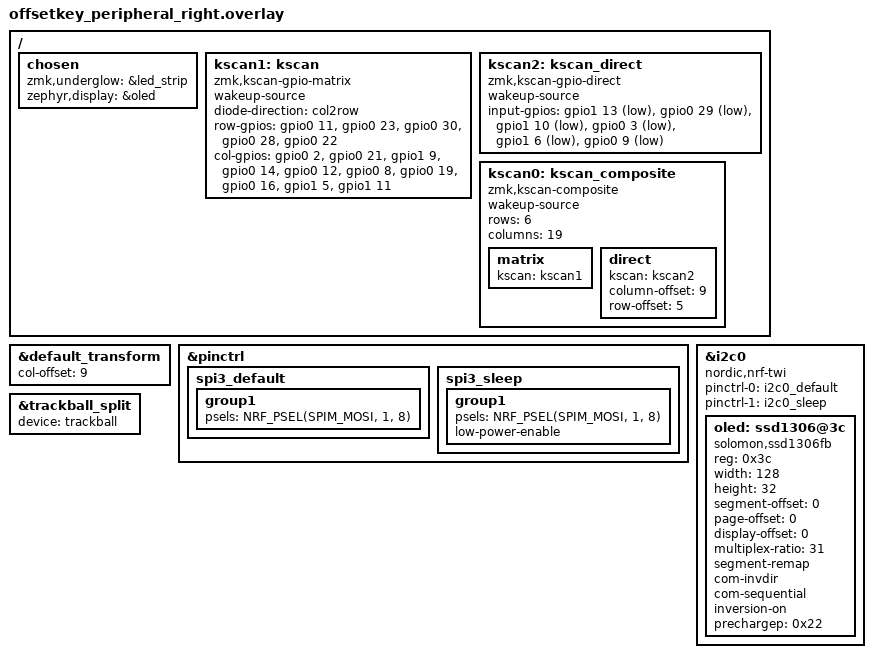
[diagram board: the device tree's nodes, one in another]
/*
 * Copyright (c) 2020 ZMK Contributors
 *
 * SPDX-License-Identifier: MIT
 */
#include <dt-bindings/zmk/input_transform.h>
#include <input/processors.dtsi>
#include <dt-bindings/led/led.h>
#include "offsetkey.dtsi"
#include "trackball.dtsi"
#include "split_input_common.dtsi"
#define SYMBOLS 2
#include "rgb.dtsi"

/ {
	chosen {
        zmk,underglow = &led_strip;
        zephyr,display = &oled;
    };

    kscan1: kscan {
        wakeup-source;
        diode-direction = "col2row";
        compatible = "zmk,kscan-gpio-matrix";
        row-gpios
            = <&gpio0 11 (GPIO_ACTIVE_HIGH | GPIO_PULL_DOWN)>
            , <&gpio0 23 (GPIO_ACTIVE_HIGH | GPIO_PULL_DOWN)>
            , <&gpio0 30  (GPIO_ACTIVE_HIGH | GPIO_PULL_DOWN)>
            , <&gpio0 28 (GPIO_ACTIVE_HIGH | GPIO_PULL_DOWN)>
            , <&gpio0 22 (GPIO_ACTIVE_HIGH | GPIO_PULL_DOWN)>
            ;
        col-gpios
            =  <&gpio0 2  GPIO_ACTIVE_HIGH>
            ,  <&gpio0 21  GPIO_ACTIVE_HIGH>
            , <&gpio1 9  GPIO_ACTIVE_HIGH>
            , <&gpio0 14  GPIO_ACTIVE_HIGH>
            , <&gpio0 12  GPIO_ACTIVE_HIGH>
            , <&gpio0 8  GPIO_ACTIVE_HIGH>  
            , <&gpio0 19  GPIO_ACTIVE_HIGH>  
            , <&gpio0 16  GPIO_ACTIVE_HIGH>  
            , <&gpio1 5  GPIO_ACTIVE_HIGH> 
            , <&gpio1 11 GPIO_ACTIVE_HIGH> 
            ;
    };

    kscan2: kscan_direct {
        compatible = "zmk,kscan-gpio-direct";
        wakeup-source;
        input-gpios
            = <&gpio1 13 (GPIO_ACTIVE_LOW | GPIO_PULL_UP)>
            , <&gpio0 29 (GPIO_ACTIVE_LOW | GPIO_PULL_UP)>
            , <&gpio1 10 (GPIO_ACTIVE_LOW | GPIO_PULL_UP)>
            , <&gpio0 3 (GPIO_ACTIVE_LOW | GPIO_PULL_UP)>
            , <&gpio1 6 (GPIO_ACTIVE_LOW | GPIO_PULL_UP)>
            , <&gpio0 9 (GPIO_ACTIVE_LOW | GPIO_PULL_UP)>
            ;
    };
//only 1.04 1.07 remain
    kscan0: kscan_composite {
        compatible = "zmk,kscan-composite";
         wakeup-source;
        rows = <6>;
        columns = <19>;

        // Include the matrix driver
        matrix {
            kscan = <&kscan1>;
        };

        // Include the direct GPIO driver...
        direct {
            kscan = <&kscan2>;
            column-offset = <9>;
            row-offset = <5>;
        };
    };
};

&default_transform {
	col-offset = <9>;
};

&pinctrl {

    spi3_default: spi3_default {
        group1 {
            psels = <NRF_PSEL(SPIM_MOSI, 1, 8)>; // WS2812_VEXT_DATA
        };
    };

    spi3_sleep: spi3_sleep {
        group1 {
            psels = <NRF_PSEL(SPIM_MOSI, 1, 8)>;
            low-power-enable;
        };
    };
};

&i2c0 {
	status = "okay";
	compatible = "nordic,nrf-twi";
    pinctrl-0 = <&i2c0_default>;
    pinctrl-1 = <&i2c0_sleep>;
    oled: ssd1306@3c {
        compatible = "solomon,ssd1306fb";
        reg = <0x3c>;
        width = <128>;
        height = <32>;
        segment-offset = <0>;
        page-offset = <0>;
        display-offset = <0>;
        multiplex-ratio = <31>;
        segment-remap;
        com-invdir;
        com-sequential;
        inversion-on;
        prechargep = <0x22>;
    };
};


&trackball_split { 
	device = <&trackball>; 
};

